VERSION ""

NS_ :

BS_:

BU_: UserApplication MCM
VAL_TABLE_ Override_State 1 "User Override" 0 "Normal" ;

BO_ 3221225472 VECTOR__INDEPENDENT_SIG_MSG: 0 Vector__XXX
 SG_ InterfaceID : 0|3@1+ (1,0) [0|0] "" Vector__XXX

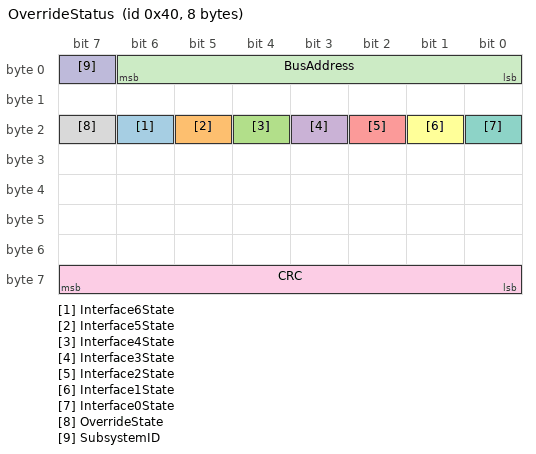
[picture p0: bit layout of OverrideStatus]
BO_ 64 OverrideStatus: 8 Vector__XXX
 SG_ Interface6State : 22|1@1+ (1,0) [0|0] "" Vector__XXX
 SG_ Interface5State : 21|1@1+ (1,0) [0|0] "" Vector__XXX
 SG_ Interface4State : 20|1@1+ (1,0) [0|0] "" Vector__XXX
 SG_ Interface3State : 19|1@1+ (1,0) [0|0] "" Vector__XXX
 SG_ Interface2State : 18|1@1+ (1,0) [0|0] "" Vector__XXX
 SG_ Interface1State : 17|1@1+ (1,0) [0|0] "" Vector__XXX
 SG_ Interface0State : 16|1@1+ (1,0) [0|0] "" Vector__XXX
 SG_ OverrideState : 23|1@1+ (1,0) [0|0] "" Vector__XXX
 SG_ CRC : 56|8@1+ (1,0) [0|0] "" Vector__XXX
 SG_ SubsystemID : 7|1@1+ (1,0) [0|0] "" Vector__XXX
 SG_ BusAddress : 0|7@1+ (1,0) [0|0] "" Vector__XXX

CM_ BO_ 3221225472 "This is a message for not used signals, created by Vector CANdb++ DBC OLE DB Provider.";
BA_DEF_ SG_  "SigType" ENUM  "Default","Range","RangeSigned","ASCII","Discrete","Control","ReferencePGN","DTC","StringDelimiter","StringLength","StringLengthControl","MessageCounter","MessageChecksum";
BA_DEF_ SG_  "GenSigEVName" STRING ;
BA_DEF_ SG_  "GenSigILSupport" ENUM  "No","Yes";
BA_DEF_ SG_  "GenSigSendType" ENUM  "Cyclic","OnWrite","OnWriteWithRepetition","OnChange","OnChangeWithRepetition","IfActive","IfActiveWithRepetition","NoSigSendType";
BA_DEF_ BO_  "GenMsgILSupport" ENUM  "No","Yes";
BA_DEF_ BU_  "NmStationAddress" INT 0 255;
BA_DEF_ BO_  "GenMsgSendType" ENUM  "cyclic","NotUsed","IfActive","NotUsed","NotUsed","NotUsed","NotUsed","NotUsed","noMsgSendType";
BA_DEF_ BO_  "GenMsgRequestable" INT 0 1;
BA_DEF_  "DBName" STRING ;
BA_DEF_  "BusType" STRING ;
BA_DEF_  "ProtocolType" STRING ;
BA_DEF_ BO_  "VFrameFormat" ENUM  "StandardCAN","ExtendedCAN","reserved","J1939PG";
BA_DEF_DEF_  "SigType" "Default";
BA_DEF_DEF_  "GenSigEVName" "Env@Nodename_@Signame";
BA_DEF_DEF_  "GenSigILSupport" "Yes";
BA_DEF_DEF_  "GenSigSendType" "NoSigSendType";
BA_DEF_DEF_  "GenMsgILSupport" "Yes";
BA_DEF_DEF_  "NmStationAddress" 254;
BA_DEF_DEF_  "GenMsgSendType" "noMsgSendType";
BA_DEF_DEF_  "GenMsgRequestable" 1;
BA_DEF_DEF_  "DBName" "";
BA_DEF_DEF_  "BusType" "CAN";
BA_DEF_DEF_  "ProtocolType" "J1939";
BA_DEF_DEF_  "VFrameFormat" "J1939PG";
BA_ "DBName" "Configuration";
BA_ "NmStationAddress" BU_ UserApplication 241;
BA_ "NmStationAddress" BU_ MCM 0;
BA_ "VFrameFormat" BO_ 64 0;
VAL_ 64 Interface6State 1 "User Override" 0 "Normal" ;
VAL_ 64 Interface5State 1 "User Override" 0 "Normal" ;
VAL_ 64 Interface4State 1 "User Override" 0 "Normal" ;
VAL_ 64 Interface3State 1 "User Override" 0 "Normal" ;
VAL_ 64 Interface2State 1 "User Override" 0 "Normal" ;
VAL_ 64 Interface1State 1 "User Override" 0 "Normal" ;
VAL_ 64 Interface0State 1 "User Override" 0 "Normal" ;
VAL_ 64 OverrideState 1 "User Override" 0 "Normal" ;
